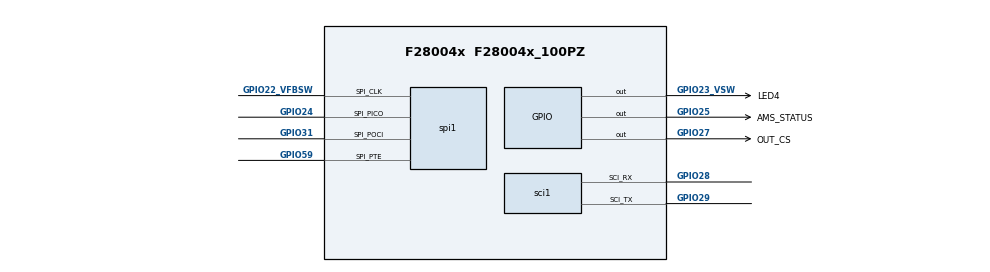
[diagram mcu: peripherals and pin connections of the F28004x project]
/**
 * @cliArgs --device "F28004x" --package "F28004x_100PZ" --part "F28004x_100PZ" --context "system" --product "C2000WARE@4.03.00.00"
 * @versions {"tool":"1.16.1+2960"}
 */

/**
 * Import the modules used in this configuration.
 */
const led   = scripting.addModule("/driverlib/board_components/led", {}, false);
const led1  = led.addInstance();
const gpio  = scripting.addModule("/driverlib/gpio.js", {}, false);
const gpio2 = gpio.addInstance();
const gpio3 = gpio.addInstance();
const sci   = scripting.addModule("/driverlib/sci.js", {}, false);
const sci1  = sci.addInstance();
const spi   = scripting.addModule("/driverlib/spi.js", {}, false);
const spi1  = spi.addInstance();

/**
 * Write custom configuration values to the imported modules.
 */
led1.$name                = "LED4";
led1.gpio.gpioPin.$assign = "GPIO23_VSW";

gpio2.$name           = "OUT_CS";
gpio2.direction       = "GPIO_DIR_MODE_OUT";
gpio2.gpioPin.$assign = "GPIO27";

gpio3.$name           = "AMS_STATUS";
gpio3.direction       = "GPIO_DIR_MODE_OUT";
gpio3.gpioPin.$assign = "GPIO25";

sci1.$name                 = "UART";
sci1.baudRates             = 9600;
sci1.sci.$assign           = "SCIA";
sci1.sci.sci_rxPin.$assign = "GPIO28";
sci1.sci.sci_txPin.$assign = "GPIO29";

spi1.$name                   = "OUT";
spi1.mode                    = "SPI_MODE_CONTROLLER";
spi1.dataWidth               = "8";
spi1.useInterrupts           = false;
spi1.transferProtocol        = "SPI_PROT_POL1PHA0";
spi1.emulationMode           = "SPI_EMULATION_FREE_RUN";
spi1.bitRate                 = 500000;
spi1.spi.$assign             = "SPIB";
spi1.spi.spi_picoPin.$assign = "GPIO24";
spi1.spi.spi_pociPin.$assign = "GPIO31";
spi1.spi.spi_clkPin.$assign  = "GPIO22_VFBSW";
spi1.spi.spi_ptePin.$assign  = "GPIO59";
